# STM32F303x register map
File version: 1.0
Registers are 32-bit, read-write, reset 0x0 unless marked. A register's access mark holds for its fields unless they carry their own. Offsets are from the block's base; [hi:lo] are bit positions; {n}, {i} and the like mark numbered series; 'fields as' and 'values as' point back to an identical list.

## EXTI — External interrupt/event controller
Base 0x40010400
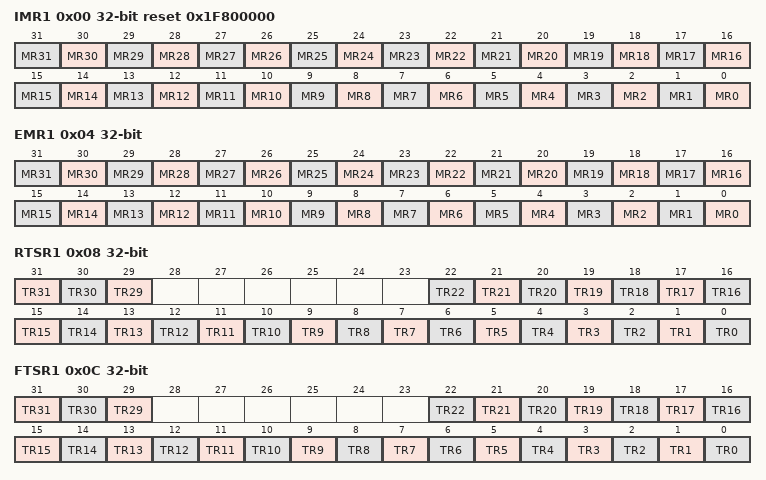
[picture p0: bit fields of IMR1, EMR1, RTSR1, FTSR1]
0x00 IMR1 reset 0x1F800000 — Interrupt mask register
  [all] fields
    0=disabled (Disable the Interrupt Mask.); 1=enabled (Enable the interrupt Mask.)
  [n] MR{n} (n=0..31) — Interrupt Mask on line {n}
0x04 EMR1 — Event mask register
  [all] fields
    values as the fields of IMR1
  [n] MR{n} (n=0..31) — Event Mask on line {n}
0x08 RTSR1 — Rising Trigger selection register
  [all] fields
    0=disabled (Disable the Rising trigger.); 1=enabled (Enable the Rising trigger.)
  [31] TR31 — Rising trigger event configuration of line 31
  [30] TR30 — Rising trigger event configuration of line 30
  [29] TR29 — Rising trigger event configuration of line 29
  [n] TR{n} (n=0..22) — Rising trigger event configuration of line {n}
0x0C FTSR1 — Falling Trigger selection register
  [all] fields
    values as the fields of RTSR1
  [31] TR31 — Falling trigger event configuration of line 31
  [30] TR30 — Falling trigger event configuration of line 30.
  [29] TR29 — Falling trigger event configuration of line 29
  [n] TR{n} (n=0..22) — Falling trigger event configuration of line {n}
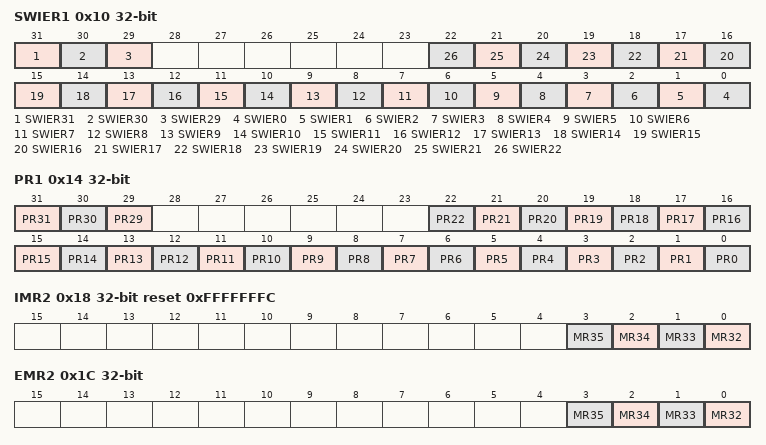
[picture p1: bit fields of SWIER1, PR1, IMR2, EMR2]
0x10 SWIER1 — Software interrupt event register
  [all] fields
    values as the fields of RTSR1
  [31] SWIER31 — Software Interrupt on line 319
  [30] SWIER30 — Software Interrupt on line 309
  [29] SWIER29 — Software Interrupt on line 29
  [n] SWIER{n} (n=0..22) — Software Interrupt on line {n}
0x14 PR1 — Pending register
  [all] fields
    0=not_pending (No interrupt pending.); 1=pending (Interrupt pending.)
  [31] PR31 — Pending bit 31
  [30] PR30 — Pending bit 30
  [29] PR29 — Pending bit 29
  [n] PR{n} (n=0..22) — Pending bit {n}
0x18 IMR2 reset 0xFFFFFFFC — Interrupt mask register
  [all] fields
    values as the fields of RTSR1
  [n-32] MR{n} (n=32..35) — Interrupt Mask on external/internal line {n}
0x1C EMR2 — Event mask register
  [all] fields
    values as the fields of RTSR1
  [n-32] MR{n} (n=32..35) — Event mask on external/internal line {n}
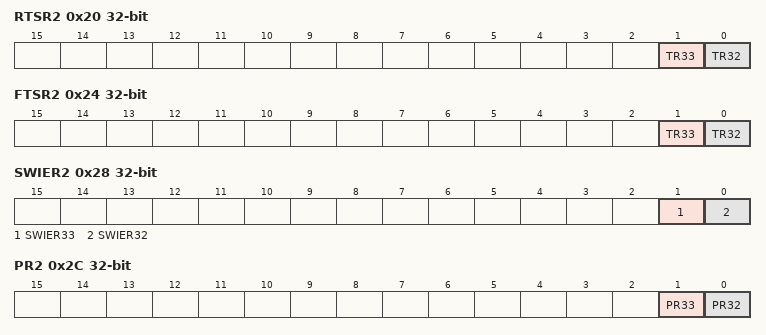
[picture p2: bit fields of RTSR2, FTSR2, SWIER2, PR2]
0x20 RTSR2 — Rising Trigger selection register
  [1] TR33 — Rising trigger event configuration bit of line 33
    values as the fields of RTSR1
  [0] TR32 — Rising trigger event configuration bit of line 32
    values as the fields of RTSR1
0x24 FTSR2 — Falling Trigger selection register
  [1] TR33 — Falling trigger event configuration bit of line 33
    values as the fields of RTSR1
  [0] TR32 — Falling trigger event configuration bit of line 32
    values as the fields of RTSR1
0x28 SWIER2 — Software interrupt event register
  [1] SWIER33 — Software interrupt on line 33
    values as the fields of RTSR1
  [0] SWIER32 — Software interrupt on line 32
    values as the fields of RTSR1
0x2C PR2 — Pending register
  [1] PR33 — Pending bit on line 33
    values as the fields of PR1
  [0] PR32 — Pending bit on line 32
    values as the fields of PR1

## PWR — Power control
Base 0x40007000
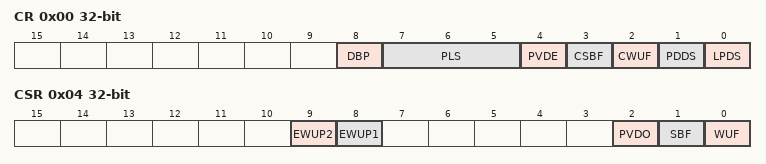
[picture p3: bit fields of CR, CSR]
0x00 CR — power control register
  [8] DBP — Disable backup domain write protection
  [7:5] PLS — PVD level selection
  [4] PVDE — Power voltage detector enable
  [3] CSBF — Clear standby flag
  [2] CWUF — Clear wakeup flag
  [1] PDDS — Power down deepsleep
  [0] LPDS — Low-power deep sleep
0x04 CSR access per field — power control/status register
  [9] EWUP2 rw — Enable WKUP2 pin
  [8] EWUP1 rw — Enable WKUP1 pin
  [2] PVDO ro — PVD output
  [1] SBF ro — Standby flag
  [0] WUF ro — Wakeup flag

## IWDG — Independent watchdog
Base 0x40003000
0x00 KR wo — Key register
  [15:0] KEY — Key value
0x04 PR — Prescaler register
  [2:0] PR — Prescaler divider
0x08 RLR reset 0xFFF — Reload register
  [11:0] RL — Watchdog counter reload value
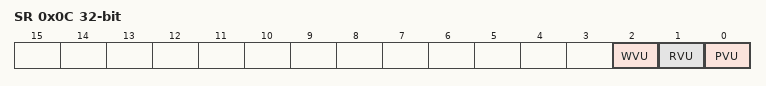
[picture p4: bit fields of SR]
0x0C SR ro — Status register
  [2] WVU — Watchdog counter window value update
  [1] RVU — Watchdog counter reload value update
  [0] PVU — Watchdog prescaler value update
0x10 WINR reset 0xFFF — Window register
  [11:0] WIN — Watchdog counter window value
